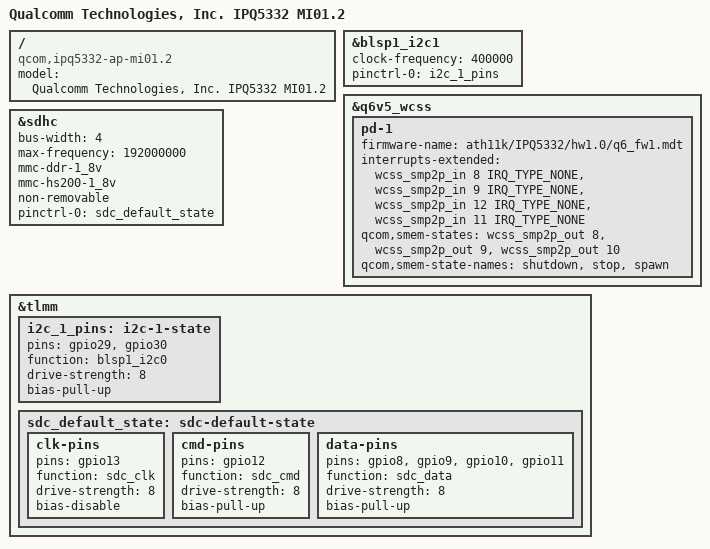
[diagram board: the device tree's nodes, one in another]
// SPDX-License-Identifier: BSD-3-Clause
/*
 * IPQ5332 AP-MI01.2 board device tree source
 *
 * Copyright (c) 2022-2023 Qualcomm Innovation Center, Inc. All rights reserved.
 */

/dts-v1/;

#include "ipq5332-rdp-common.dtsi"

/ {
	model = "Qualcomm Technologies, Inc. IPQ5332 MI01.2";
	compatible = "qcom,ipq5332-ap-mi01.2", "qcom,ipq5332";
};

&blsp1_i2c1 {
	clock-frequency  = <400000>;
	pinctrl-0 = <&i2c_1_pins>;
	pinctrl-names = "default";
	status = "okay";
};

&q6v5_wcss {
	pd-1 {
		firmware-name = "ath11k/IPQ5332/hw1.0/q6_fw1.mdt";
		interrupts-extended = <&wcss_smp2p_in 8 IRQ_TYPE_NONE>,
				      <&wcss_smp2p_in 9 IRQ_TYPE_NONE>,
				      <&wcss_smp2p_in 12 IRQ_TYPE_NONE>,
				      <&wcss_smp2p_in 11 IRQ_TYPE_NONE>;
		interrupt-names = "fatal",
				  "ready",
				  "spawn-ack",
				  "stop-ack";

		qcom,smem-states = <&wcss_smp2p_out 8>,
				   <&wcss_smp2p_out 9>,
				   <&wcss_smp2p_out 10>;
		qcom,smem-state-names = "shutdown",
					"stop",
					"spawn";
	};
};

&sdhc {
	bus-width = <4>;
	max-frequency = <192000000>;
	mmc-ddr-1_8v;
	mmc-hs200-1_8v;
	non-removable;
	pinctrl-0 = <&sdc_default_state>;
	pinctrl-names = "default";
	status = "okay";
};

&tlmm {
	i2c_1_pins: i2c-1-state {
		pins = "gpio29", "gpio30";
		function = "blsp1_i2c0";
		drive-strength = <8>;
		bias-pull-up;
	};

	sdc_default_state: sdc-default-state {
		clk-pins {
			pins = "gpio13";
			function = "sdc_clk";
			drive-strength = <8>;
			bias-disable;
		};

		cmd-pins {
			pins = "gpio12";
			function = "sdc_cmd";
			drive-strength = <8>;
			bias-pull-up;
		};

		data-pins {
			pins = "gpio8", "gpio9", "gpio10", "gpio11";
			function = "sdc_data";
			drive-strength = <8>;
			bias-pull-up;
		};
	};
};
